# MKW41Z4 register map
Vendor: Freescale Semiconductor, Inc.; Series: Kinetis_W; File version: 1.6
CPU: CM0PLUS r0p0, little endian, no MPU, no FPU, VTOR, 2 interrupt priority bits
Registers are 16-bit, read-write, no defined reset value unless marked. A register's access mark holds for its fields unless they carry their own. Offsets are from the block's base; [hi:lo] are bit positions.

## RSIM_REGS — RSIM
Base 0x40059000
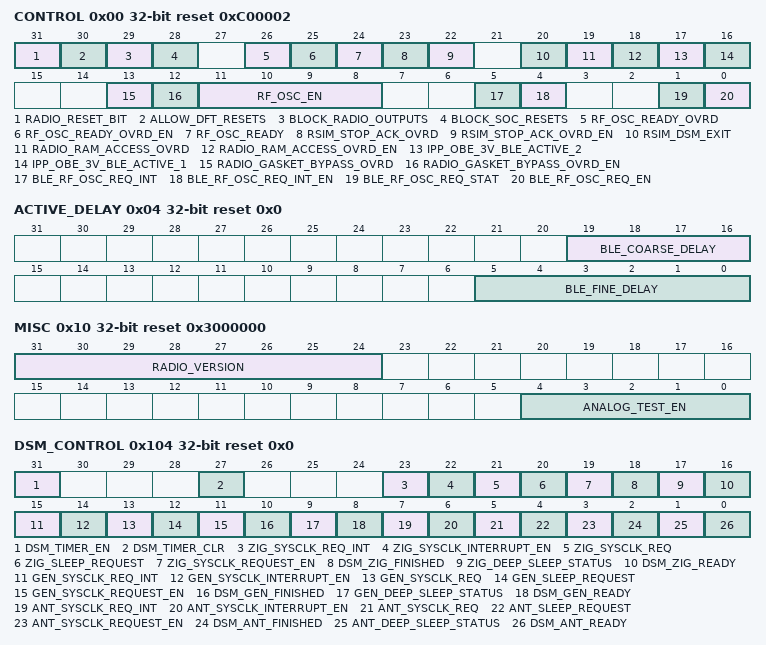
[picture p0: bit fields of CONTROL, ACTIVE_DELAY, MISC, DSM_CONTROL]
0x00 CONTROL 32-bit reset 0xC00002 — Radio System Control
  [31] RADIO_RESET_BIT — Software Reset for the Radio
  [30] ALLOW_DFT_RESETS — Allow the DFT Reset Pin to Reset the Radio
  [29] BLOCK_RADIO_OUTPUTS
  [28] BLOCK_SOC_RESETS — Block SoC Resets of the Radio
  [26] RF_OSC_READY_OVRD — RF Ref Osc Ready Override
  [25] RF_OSC_READY_OVRD_EN — RF Ref Osc Ready Override Enable
  [24] RF_OSC_READY ro — RF Ref Osc Ready
  [23] RSIM_STOP_ACK_OVRD — Stop Acknowledge Override
  [22] RSIM_STOP_ACK_OVRD_EN — Stop Acknowledge Override Enable
  [20] RSIM_DSM_EXIT — BLE Force Deep Sleep Mode Exit
  [19] RADIO_RAM_ACCESS_OVRD — Radio RAM Access Override
  [18] RADIO_RAM_ACCESS_OVRD_EN — Radio RAM Access Override Enable
  [17] IPP_OBE_3V_BLE_ACTIVE_2
  [16] IPP_OBE_3V_BLE_ACTIVE_1
  [13] RADIO_GASKET_BYPASS_OVRD — Radio Gasket Bypass Override
  [12] RADIO_GASKET_BYPASS_OVRD_EN — Radio Gasket Bypass Override Enable
  [11:8] RF_OSC_EN — RF Ref Osc Enable Select
    0=RF Ref Osc will be controlled by the SoC, external pin, or a link layer; 1=RF Ref Osc on in Run/Wait; 3=RF Ref Osc on in Stop; 7=RF Ref Osc on in VLPR/VLPW; 15=RF Ref Osc on in VLPS
  [5] BLE_RF_OSC_REQ_INT — BLE Ref Osc (Sysclk) Request Interrupt Flag
  [4] BLE_RF_OSC_REQ_INT_EN — BLE Ref Osc (Sysclk) Request Interrupt Enable
  [1] BLE_RF_OSC_REQ_STAT ro — BLE Ref Osc (Sysclk) Request Status
  [0] BLE_RF_OSC_REQ_EN — BLE Ref Osc (Sysclk) Request Enable
0x04 ACTIVE_DELAY 32-bit reset 0x0 — Radio Active Early Warning
  [19:16] BLE_COARSE_DELAY — BLE Active Coarse Delay
  [5:0] BLE_FINE_DELAY — BLE Active Fine Delay
0x08 MAC_MSB 32-bit ro reset 0x0 — Radio MAC Address
  [7:0] MAC_ADDR_MSB — Radio MAC Address MSB
0x0C MAC_LSB 32-bit ro reset 0x0 — Radio MAC Address
  [31:0] MAC_ADDR_LSB — Radio MAC Address LSB
0x10 MISC 32-bit reset 0x3000000 — Radio Miscellaneous
  [31:24] RADIO_VERSION — Radio Version ID number
  [4:0] ANALOG_TEST_EN — RSIM Analog Test Mux Enables
0x100 DSM_TIMER 32-bit ro reset 0x0 — Deep Sleep Timer
  [23:0] DSM_TIMER — Deep Sleep Mode Timer
0x104 DSM_CONTROL 32-bit reset 0x0 — Deep Sleep Timer Control
  [31] DSM_TIMER_EN — Deep Sleep Mode Timer Enable
  [27] DSM_TIMER_CLR — Deep Sleep Mode Timer Clear
  [23] ZIG_SYSCLK_REQ_INT ro — Interrupt Flag from an 802.15.4 Link Layer RF OSC Request
  [22] ZIG_SYSCLK_INTERRUPT_EN — 802.15.4 Link Layer RF OSC Request Interrupt Enable
  [21] ZIG_SYSCLK_REQ ro — 802.15.4 Link Layer RF OSC Request Status
  [20] ZIG_SLEEP_REQUEST ro — 802.15.4 Link Layer Deep Sleep Requested
  [19] ZIG_SYSCLK_REQUEST_EN — Enable 802.15.4 Link Layer to Request RF OSC
  [18] DSM_ZIG_FINISHED ro — 802.15.4 Deep Sleep Time Finished
  [17] ZIG_DEEP_SLEEP_STATUS ro — 802.15.4 Link Layer Deep Sleep Mode Status
  [16] DSM_ZIG_READY ro — 802.15.4 Ready for Deep Sleep Mode
  [15] GEN_SYSCLK_REQ_INT ro — Interrupt Flag from an Generic FSK Link Layer RF OSC Request
  [14] GEN_SYSCLK_INTERRUPT_EN — Generic FSK Link Layer RF OSC Request Interrupt Enable
  [13] GEN_SYSCLK_REQ ro — Generic FSK Link Layer RF OSC Request Status
  [12] GEN_SLEEP_REQUEST ro — Generic FSK Link Layer Deep Sleep Requested
  [11] GEN_SYSCLK_REQUEST_EN — Enable Generic FSK Link Layer to Request RF OSC
  [10] DSM_GEN_FINISHED ro — Generic FSK Deep Sleep Time Finished
  [9] GEN_DEEP_SLEEP_STATUS ro — Generic FSK Link Layer Deep Sleep Mode Status
  [8] DSM_GEN_READY ro — Generic FSK Ready for Deep Sleep Mode
  [7] ANT_SYSCLK_REQ_INT — Interrupt Flag from an ANT Link Layer RF OSC Request
  [6] ANT_SYSCLK_INTERRUPT_EN — ANT Link Layer RF OSC Request Interrupt Enable
  [5] ANT_SYSCLK_REQ ro — ANT Link Layer RF OSC Request Status
  [4] ANT_SLEEP_REQUEST ro — ANT Link Layer Deep Sleep Requested
  [3] ANT_SYSCLK_REQUEST_EN — Enable ANT Link Layer to Request RF OSC
  [2] DSM_ANT_FINISHED ro — ANT Deep Sleep Time Finished
  [1] ANT_DEEP_SLEEP_STATUS ro — ANT Link Layer Deep Sleep Mode Status
  [0] DSM_ANT_READY ro — ANT Ready for Deep Sleep Mode
0x108 DSM_OSC_OFFSET 32-bit reset 0x0 — Deep Sleep Wakeup Time Offset
  [9:0] DSM_OSC_STABILIZE_TIME — Deep Sleep Wakeup RF OSC Stabilize Time
0x10C ANT_SLEEP 32-bit reset 0x0 — ANT Link Layer Sleep Time
  [23:0] ANT_SLEEP_TIME
0x110 ANT_WAKE 32-bit reset 0x0 — ANT Link Layer Wake Time
  [23:0] ANT_WAKE_TIME
0x114 ZIG_SLEEP 32-bit reset 0x0 — 802.15.4 Link Layer Sleep Time
  [23:0] ZIG_SLEEP_TIME
0x118 ZIG_WAKE 32-bit reset 0x0 — 802.15.4 Link Layer Wake Time
  [23:0] ZIG_WAKE_TIME
0x11C GEN_SLEEP 32-bit reset 0x0 — Generic FSK Link Layer Sleep Time
  [23:0] GEN_SLEEP_TIME
0x120 GEN_WAKE 32-bit reset 0x0 — Generic FSK Link Layer Wake Time
  [23:0] GEN_WAKE_TIME
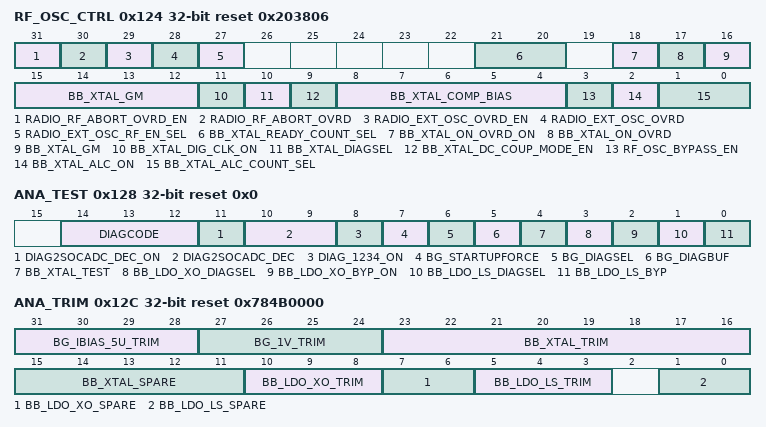
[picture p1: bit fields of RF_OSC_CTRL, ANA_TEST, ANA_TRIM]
0x124 RF_OSC_CTRL 32-bit reset 0x203806 — Radio Oscillator Control
  [31] RADIO_RF_ABORT_OVRD_EN — Radio RF Abort Override Enable
  [30] RADIO_RF_ABORT_OVRD — Radio RF Abort Override
  [29] RADIO_EXT_OSC_OVRD_EN — Radio External Request for RF OSC Override Enable
  [28] RADIO_EXT_OSC_OVRD — Radio External Request for RF OSC Override
  [27] RADIO_EXT_OSC_RF_EN_SEL — Radio External Request for RF OSC Select
  [21:20] BB_XTAL_READY_COUNT_SEL — rmap_bb_xtal_ready_count_sel_hv[1:0]
  [18] BB_XTAL_ON_OVRD_ON — rmap_bb_xtal_on_ovrd_on_hv
  [17] BB_XTAL_ON_OVRD — rmap_bb_xtal_on_ovrd_hv
  [16:12] BB_XTAL_GM — rmap_bb_xtal_gm_hv[4:0]
  [11] BB_XTAL_DIG_CLK_ON — rmap_bb_xtal_dig_clk_on_hv
  [10] BB_XTAL_DIAGSEL — rmap_bb_xtal_diagsel_hv
  [9] BB_XTAL_DC_COUP_MODE_EN — rmap_bb_xtal_dc_coup_mode_en_hv
  [8:4] BB_XTAL_COMP_BIAS — rmap_bb_xtal_comp_bias_hv[4:0]
  [3] RF_OSC_BYPASS_EN — RF Ref Osc Bypass Enable
  [2] BB_XTAL_ALC_ON — rmap_bb_xtal_alc_on_hv
  [1:0] BB_XTAL_ALC_COUNT_SEL — rmap_bb_xtal_alc_count_sel_hv[1:0]
0x128 ANA_TEST 32-bit reset 0x0 — Radio Analog Test Registers
  [14:12] DIAGCODE — rmap_diagcode_hv[2:0]
  [11] DIAG2SOCADC_DEC_ON — rmap_diag2socadc_dec_on_hv
  [10:9] DIAG2SOCADC_DEC — rmap_diag2socadc_dec_hv[1:0]
  [8] DIAG_1234_ON — rmap_diag_1234_on_hv
  [7] BG_STARTUPFORCE — rmap_bg_startupforce_hv
  [6] BG_DIAGSEL — rmap_bg_diagsel_hv
  [5] BG_DIAGBUF — rmap_bg_diagbuf_hv
  [4] BB_XTAL_TEST — rmap_bb_xtal_test_en_hv
  [3] BB_LDO_XO_DIAGSEL — rmap_bb_ldo_xo_diagsel_hv
  [2] BB_LDO_XO_BYP_ON — rmap_bb_ldo_xo_byp_on_hv
  [1] BB_LDO_LS_DIAGSEL — rmap_bb_ldo_ls_diagsel_hv
  [0] BB_LDO_LS_BYP — rmap_bb_ldo_ls_byp_hv
0x12C ANA_TRIM 32-bit reset 0x784B0000 — Radio Analog Trim Registers
  [31:28] BG_IBIAS_5U_TRIM — rmap_bg_ibias_5u_trim_hv[3:0]
  [27:24] BG_1V_TRIM — rmap_bg_1v_trim_hv[3:0]
  [23:16] BB_XTAL_TRIM — rmap_bb_xtal_trim_hv[7:0]
  [15:11] BB_XTAL_SPARE — rmap_bb_xtal_spare_hv[4:0]
  [10:8] BB_LDO_XO_TRIM — rmap_bb_ldo_xo_trim_hv[2:0]
  [7:6] BB_LDO_XO_SPARE — rmap_bb_ldo_xo_spare_hv[1:0]
  [5:3] BB_LDO_LS_TRIM — rmap_bb_ldo_ls_trim_hv[2:0]
  [1:0] BB_LDO_LS_SPARE — rmap_bb_ldo_ls_spare_hv[1:0]
